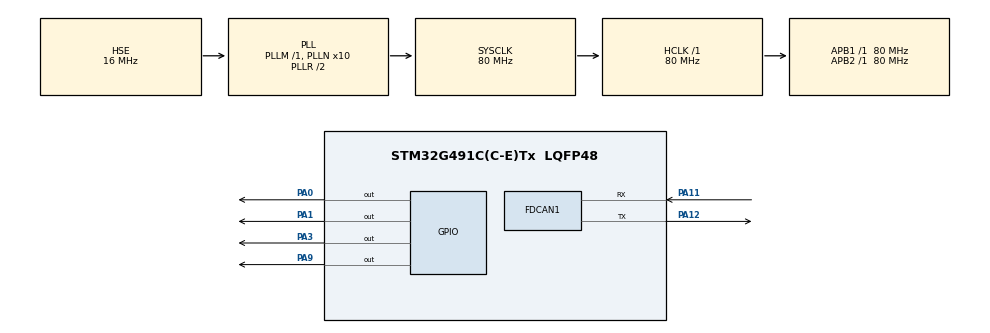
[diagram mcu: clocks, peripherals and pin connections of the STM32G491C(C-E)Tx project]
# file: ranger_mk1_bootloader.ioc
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FDCAN1.CalculateBaudRateNominal=1000000
FDCAN1.CalculateTimeBitNominal=1000
FDCAN1.CalculateTimeQuantumNominal=200.0
Mcu.Family=STM32G4
Mcu.Name=STM32G491C(C-E)Tx
Mcu.Package=LQFP48
NVIC.PriorityGroup=NVIC_PRIORITYGROUP_4
PA0.Signal=GPIO_Output
PA1.Signal=GPIO_Output
PA11.Mode=FDCAN_Activate
PA11.Signal=FDCAN1_RX
PA12.Mode=FDCAN_Activate
PA12.Signal=FDCAN1_TX
PA13.Signal=SYS_JTMS-SWDIO
PA14.Signal=SYS_JTCK-SWCLK
PA3.Signal=GPIO_Output
PA4.Signal=SPI1_NSS
PA5.Signal=SPI1_SCK
PA6.Signal=SPI1_MISO
PA7.Signal=SPI1_MOSI
PA9.PinState=GPIO_PIN_SET
PA9.Signal=GPIO_Output
PB13.Signal=SPI2_SCK
PB14.Signal=SPI2_MISO
PB15.Signal=SPI2_MOSI
PB3.Signal=SYS_JTDO-SWO
PF0-OSC_IN.Mode=HSE-External-Oscillator
PF0-OSC_IN.Signal=RCC_OSC_IN
PF1-OSC_OUT.Mode=HSE-External-Oscillator
PF1-OSC_OUT.Signal=RCC_OSC_OUT
ProjectManager.HeapSize=0x200
ProjectManager.StackSize=0x400
ProjectManager.TargetToolchain=STM32CubeIDE
RCC.ADC12Freq_Value=80000000
RCC.ADC345Freq_Value=80000000
RCC.AHBFreq_Value=80000000
RCC.APB1Freq_Value=80000000
RCC.APB1TimFreq_Value=80000000
RCC.APB2Freq_Value=80000000
RCC.APB2TimFreq_Value=80000000
RCC.CortexFreq_Value=80000000
RCC.EXTERNAL_CLOCK_VALUE=12288000
RCC.HCLKFreq_Value=80000000
RCC.HSE_VALUE=16000000
RCC.HSI48_VALUE=48000000
RCC.HSI_VALUE=16000000
RCC.LSE_VALUE=32768
RCC.PLLN=10
RCC.PLLSourceVirtual=RCC_PLLSOURCE_HSE
RCC.SYSCLKFreq_VALUE=80000000
RCC.SYSCLKSource=RCC_SYSCLKSOURCE_PLLCLK
RCC.VCOOutputFreq_Value=160000000
VP_SYS_VS_DBSignals.Mode=DisableDeadBatterySignals
board=custom

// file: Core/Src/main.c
/* USER CODE BEGIN Header */
/**
  ******************************************************************************
  * @file           : main.c
  * @brief          : Main program body
  ******************************************************************************
  */
/* USER CODE END Header */

#include "main.h"

/* USER CODE BEGIN Includes */
#include "ranger_can.h"
#include "ranger_bootloader.h"
/* USER CODE END Includes */

FDCAN_HandleTypeDef hfdcan1;

void SystemClock_Config(void);
static void MX_GPIO_Init(void);
static void MX_FDCAN1_Init(void);

int main(void)
{
  HAL_Init();

  SystemClock_Config();

  MX_GPIO_Init();
  MX_FDCAN1_Init();

  /* Initialize Ranger layers */
  //ranger_can_init();
  ranger_bootloader_init();

  /* Main loop */
  while (1)
  {
	  ranger_bootloader_task();
  }
}

void SystemClock_Config(void)
{
  RCC_OscInitTypeDef RCC_OscInitStruct = {0};
  RCC_ClkInitTypeDef RCC_ClkInitStruct = {0};

  HAL_PWREx_ControlVoltageScaling(PWR_REGULATOR_VOLTAGE_SCALE1);

  RCC_OscInitStruct.OscillatorType = RCC_OSCILLATORTYPE_HSE;
  RCC_OscInitStruct.HSEState = RCC_HSE_ON;
  RCC_OscInitStruct.PLL.PLLState = RCC_PLL_ON;
  RCC_OscInitStruct.PLL.PLLSource = RCC_PLLSOURCE_HSE;
  RCC_OscInitStruct.PLL.PLLM = RCC_PLLM_DIV1;
  RCC_OscInitStruct.PLL.PLLN = 10;
  RCC_OscInitStruct.PLL.PLLP = RCC_PLLP_DIV2;
  RCC_OscInitStruct.PLL.PLLQ = RCC_PLLQ_DIV2;
  RCC_OscInitStruct.PLL.PLLR = RCC_PLLR_DIV2;

  if (HAL_RCC_OscConfig(&RCC_OscInitStruct) != HAL_OK)
  {
    Error_Handler();
  }

  RCC_ClkInitStruct.ClockType = RCC_CLOCKTYPE_HCLK |
                                RCC_CLOCKTYPE_SYSCLK |
                                RCC_CLOCKTYPE_PCLK1 |
                                RCC_CLOCKTYPE_PCLK2;

  RCC_ClkInitStruct.SYSCLKSource = RCC_SYSCLKSOURCE_PLLCLK;
  RCC_ClkInitStruct.AHBCLKDivider = RCC_SYSCLK_DIV1;
  RCC_ClkInitStruct.APB1CLKDivider = RCC_HCLK_DIV1;
  RCC_ClkInitStruct.APB2CLKDivider = RCC_HCLK_DIV1;

  if (HAL_RCC_ClockConfig(&RCC_ClkInitStruct, FLASH_LATENCY_2) != HAL_OK)
  {
    Error_Handler();
  }
}

static void MX_FDCAN1_Init(void)
{
  hfdcan1.Instance = FDCAN1;
  hfdcan1.Init.ClockDivider = FDCAN_CLOCK_DIV1;
  hfdcan1.Init.FrameFormat = FDCAN_FRAME_CLASSIC;
  hfdcan1.Init.Mode = FDCAN_MODE_NORMAL;
  hfdcan1.Init.AutoRetransmission = ENABLE;
  hfdcan1.Init.TransmitPause = DISABLE;
  hfdcan1.Init.ProtocolException = DISABLE;

  /*
   * 1 Mbit/s nominal CAN timing
   */
  hfdcan1.Init.NominalPrescaler = 8;
  hfdcan1.Init.NominalSyncJumpWidth = 2;
  hfdcan1.Init.NominalTimeSeg1 = 7;
  hfdcan1.Init.NominalTimeSeg2 = 2;

  /* Required but unused in classic CAN */
  hfdcan1.Init.DataPrescaler = 1;
  hfdcan1.Init.DataSyncJumpWidth = 1;
  hfdcan1.Init.DataTimeSeg1 = 1;
  hfdcan1.Init.DataTimeSeg2 = 1;

  hfdcan1.Init.StdFiltersNbr = 1;
  hfdcan1.Init.ExtFiltersNbr = 0;
  hfdcan1.Init.TxFifoQueueMode = FDCAN_TX_FIFO_OPERATION;

  if (HAL_FDCAN_Init(&hfdcan1) != HAL_OK)
  {
    Error_Handler();
  }

  /* NOTE:
   * No filter configuration here.
   * ranger_can.c owns all CAN filtering and runtime reconfiguration.
   */
}

static void MX_GPIO_Init(void)
{
  GPIO_InitTypeDef GPIO_InitStruct = {0};

  __HAL_RCC_GPIOF_CLK_ENABLE();
  __HAL_RCC_GPIOA_CLK_ENABLE();
  __HAL_RCC_GPIOB_CLK_ENABLE();

  HAL_GPIO_WritePin(GPIOA, GPIO_PIN_0 | GPIO_PIN_1 | GPIO_PIN_3, GPIO_PIN_RESET);
  HAL_GPIO_WritePin(GPIOA, GPIO_PIN_9, GPIO_PIN_SET);

  GPIO_InitStruct.Pin = GPIO_PIN_0 | GPIO_PIN_1 | GPIO_PIN_3 | GPIO_PIN_9;
  GPIO_InitStruct.Mode = GPIO_MODE_OUTPUT_PP;
  GPIO_InitStruct.Pull = GPIO_NOPULL;
  GPIO_InitStruct.Speed = GPIO_SPEED_FREQ_LOW;
  HAL_GPIO_Init(GPIOA, &GPIO_InitStruct);

  GPIO_InitStruct.Pin = GPIO_PIN_4 | GPIO_PIN_5 | GPIO_PIN_6 | GPIO_PIN_7;
  GPIO_InitStruct.Mode = GPIO_MODE_AF_PP;
  GPIO_InitStruct.Pull = GPIO_NOPULL;
  GPIO_InitStruct.Speed = GPIO_SPEED_FREQ_LOW;
  GPIO_InitStruct.Alternate = GPIO_AF5_SPI1;
  HAL_GPIO_Init(GPIOA, &GPIO_InitStruct);

  GPIO_InitStruct.Pin = GPIO_PIN_13 | GPIO_PIN_14 | GPIO_PIN_15;
  GPIO_InitStruct.Mode = GPIO_MODE_AF_PP;
  GPIO_InitStruct.Pull = GPIO_NOPULL;
  GPIO_InitStruct.Speed = GPIO_SPEED_FREQ_LOW;
  GPIO_InitStruct.Alternate = GPIO_AF5_SPI2;
  HAL_GPIO_Init(GPIOB, &GPIO_InitStruct);
}

/**
  * @brief  Error handler
  */
void Error_Handler(void)
{
  __disable_irq();
  while (1)
  {
  }
}
